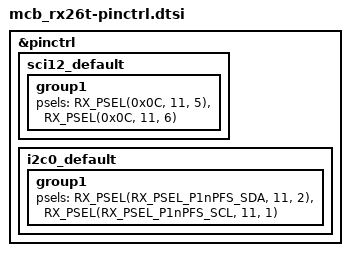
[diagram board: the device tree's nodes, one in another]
/*
 * Copyright (c) 2025 Renesas Electronics Corporation
 *
 * SPDX-License-Identifier: Apache-2.0
 */

&pinctrl {
	sci12_default: sci12_default {
		group1 {
			psels = <RX_PSEL(0x0C, 11, 5)>, /* TX - PB5 */
				<RX_PSEL(0x0C, 11, 6)>; /* RX - PB6 */
		};
	};

	i2c0_default: i2c0_default {
		group1 {
			psels = <RX_PSEL(RX_PSEL_P1nPFS_SDA, 11, 2)>, /* SDA0 PB2*/
				<RX_PSEL(RX_PSEL_P1nPFS_SCL, 11, 1)>; /* SCL0 PB1*/
		};
	};
};
